# A31G33x register map
Vendor: VENDOR ABOV Semiconductor Co., Ltd.; Series: A31G33x; File version: 1.0
CPU: CM0+ r0p1, little endian, no MPU, no FPU, VTOR, 2 interrupt priority bits
Registers are 32-bit, read-only, no defined reset value unless marked. A register's access mark holds for its fields unless they carry their own. Offsets are from the block's base; [hi:lo] are bit positions; {n}, {i} and the like mark numbered series; 'fields as' and 'values as' point back to an identical list.

## COA0 — Configuration Option Area Page 0: System Related Trimming Value
Base 0x1FFF2000
{0x0+4i} TRIM{i:02} (i=0..17) — System Related Trim Value {i:02}
0x48 TS_FREQ_T30 reset 0x0 — Temperature Sensor Output Frequency acquired at 30 degrees Celsius [Hz]
  [23:0] F_T30
0x4C TS_FREQ_T85 reset 0x0 — Temperature Sensor Output Frequency acquired at 85 degrees Celsius [Hz]
  [23:0] F_T85
0x50 CONF_MF1CNFIG — Manufacture Information 1
  [31:0] XYCDN — X and Y Coordinates
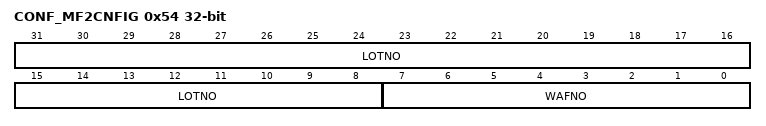
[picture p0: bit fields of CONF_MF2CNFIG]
0x54 CONF_MF2CNFIG — Manufacture Information 2
  [31:8] LOTNO — Lot Number [23:0]
  [7:0] WAFNO — Wafer Number
0x58 CONF_MF3CNFIG — Manufacture Information 3
  [31:0] LOTNO — Lot Number [55:24]
0x5C CONF_MF4CNFIG — Manufacture Information 4
  [31:0] LOTNO — Lot Number [87:56]
{0x0+4i} TRIM{i} (i=24..26) — System Related Trim Value {i}
0x6C TS_FREQ_T105 reset 0x0 — Temperature Sensor Output Frequency acquired at 105 degrees Celsius [Hz]
  [23:0] F_T105
{0x0+4i} TRIM{i} (i=28..31) — System Related Trim Value {i}

## COA1 — Configuration Option Area Page 1: User Option
Base 0x1FFF3000
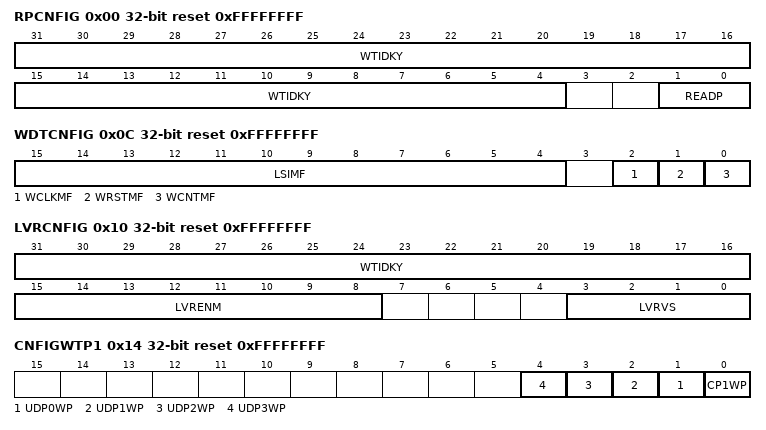
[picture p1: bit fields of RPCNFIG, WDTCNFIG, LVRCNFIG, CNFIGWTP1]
0x00 RPCNFIG reset 0xFFFFFFFF (reset mask 0xFFFFFFFC) — Configuration for Read Protection
  [31:4] WTIDKY — Write Identification Key (0x69c8a27)
    0x69C8A27=Value (Key Value (0x69c8a27))
  [1:0] READP — Read Protection for Flash Memory Area
    3=Level0 (No restriction for read/erase/write.); 2=Level1 (1. Not readable/erasable/writable by 'Debug' 2. Bulk erasable only by 'Debug' 3. Readable/erasable/writable by 'Instruction from Flash Memory and RAM'); 0=Level2 (1. Not readable/erasable/writable by 'Debug' / 'Instruction from RAM' 2. Bulk erasable only by 'Instruction from RAM' / 'Debug' 3. Readable/erasable/writable by 'Instruction from Flash Memory')
0x0C WDTCNFIG reset 0xFFFFFFFF (reset mask 0xFFFF0008) — Configuration for Watch-Dog Timer
  [15:4] LSIMF — Low Speed Internal RC Oscillator(LSI) Master Configuration
    0x96D=By S/W (CLKSRCR Register) (0x96d); 0x2A7=AlwaysEnableExceptDeepSleep (Always Enable Except for Deep Sleep (0x2a7)); 0xFFF=AlwaysEnable
  [2] WCLKMF — Watch-Dog Timer Clock Selection Master Configuration
    0=By S/W (PPCLKSR Register); 1=AlwaysLSI
  [1] WRSTMF — Watch-Dog Timer Reset Enable Master Configuration
    0=AlwaysEnable; 1=By S/W (WDTCR Register)
  [0] WCNTMF — Watch-Dog Timer Counter Enable Master Configuration
    0=AlwaysEnable; 1=By S/W (WDTCR Register)
0x10 LVRCNFIG reset 0xFFFFFFFF (reset mask 0xFFFF00F0) — Configuration for Low Voltage Reset
  [31:16] WTIDKY — Write Identification Key (0x9D58)
    0x9D58=Value (Key Value (0x9D58))
  [15:8] LVRENM — LVR Reset Operation Control Master Configuration
    170=By S/W (LVRCR Register) (0xaa); 255=Always Enable (0xff)
  [3:0] LVRVS — LVR Voltage Selection
    15=1p68V (1.68V); 12=1p94V (1.94V); 11=2p03V (2.03V); 10=2p16V (2.16V); 9=2p35V (2.35V); 8=2p52V (2.52V); 7=2p72V (2.72V); 6=3p10V (3.10V); 5=3p24V (3.24V); 4=3p66V (3.66V); 3=3p79V (3.79V); 2=4p11V (4.11V); 1=4p28V (4.28V); 0=4p57V (4.57V)
0x14 CNFIGWTP1 reset 0xFFFFFFFF (reset mask 0xFFFFFFE0) — Configure Option Page Erase/Write Protection 1
  [all] fields
    0=Enable protection. (Not erasable/writable by instruction); 1=Disable protection. (Erasable/writable by instruction)
  [n+1] UDP{n}WP (n=0..3) — User Data Page {n} Erase/Write Protection
  [0] CP1WP — Configure Option Page 1 Erase/Write Protection
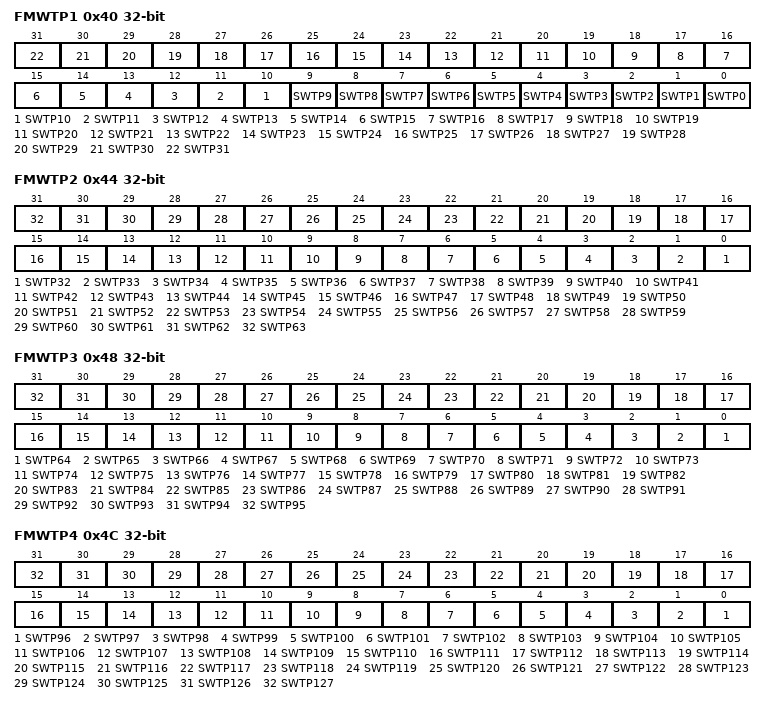
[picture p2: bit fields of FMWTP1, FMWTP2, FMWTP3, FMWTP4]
0x40 FMWTP1 — Flash Memory Erase/Write Protection 1
  [all] fields
    0=Enable (Protect 'flash memory sector n erase/write'); 1=Disable (Permit 'flash memory sector n erase/write')
  [n] SWTP{n} (n=0..31) — Flash Memory Erase/Write Protection {n}
0x44 FMWTP2 — Flash Memory Erase/Write Protection 2
  [all] fields
    values as the fields of FMWTP1
  [n-32] SWTP{n} (n=32..63) — Flash Memory Erase/Write Protection {n}
0x48 FMWTP3 — Flash Memory Erase/Write Protection 3
  [all] fields
    values as the fields of FMWTP1
  [n-64] SWTP{n} (n=64..95) — Flash Memory Erase/Write Protection {n}
0x4C FMWTP4 — Flash Memory Erase/Write Protection 4
  [all] fields
    values as the fields of FMWTP1
  [n-96] SWTP{n} (n=96..127) — Flash Memory Erase/Write Protection {n}

## COA2 — Configuration Option Area Page 2: User Data Area 0
Base 0x1FFF4000
Same registers: COA3 0x1FFF4200, COA4 0x1FFF4400, COA5 0x1FFF4600
{0x0+4i} UDATA{i:02} (i=0..99) — User Data {i:02}
{0x0+4i} UDATA{i} (i=100..127) — User Data {i}
